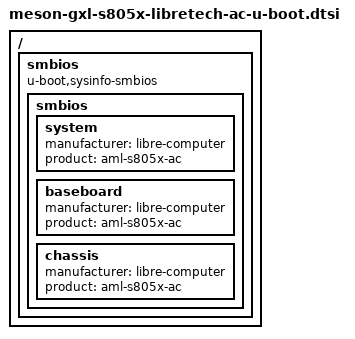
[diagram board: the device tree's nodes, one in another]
// SPDX-License-Identifier: (GPL-2.0+ OR MIT)
/*
 * Copyright (c) 2019 BayLibre, SAS.
 * Author: Neil Armstrong <narmstrong@baylibre.com>
 */

#include "meson-gxl-u-boot.dtsi"

/ {
	smbios {
		compatible = "u-boot,sysinfo-smbios";

		smbios {
			system {
				manufacturer = "libre-computer";
				product = "aml-s805x-ac";
			};

			baseboard {
				manufacturer = "libre-computer";
				product = "aml-s805x-ac";
			};

			chassis {
				manufacturer = "libre-computer";
				product = "aml-s805x-ac";
			};
		};
	};
};
